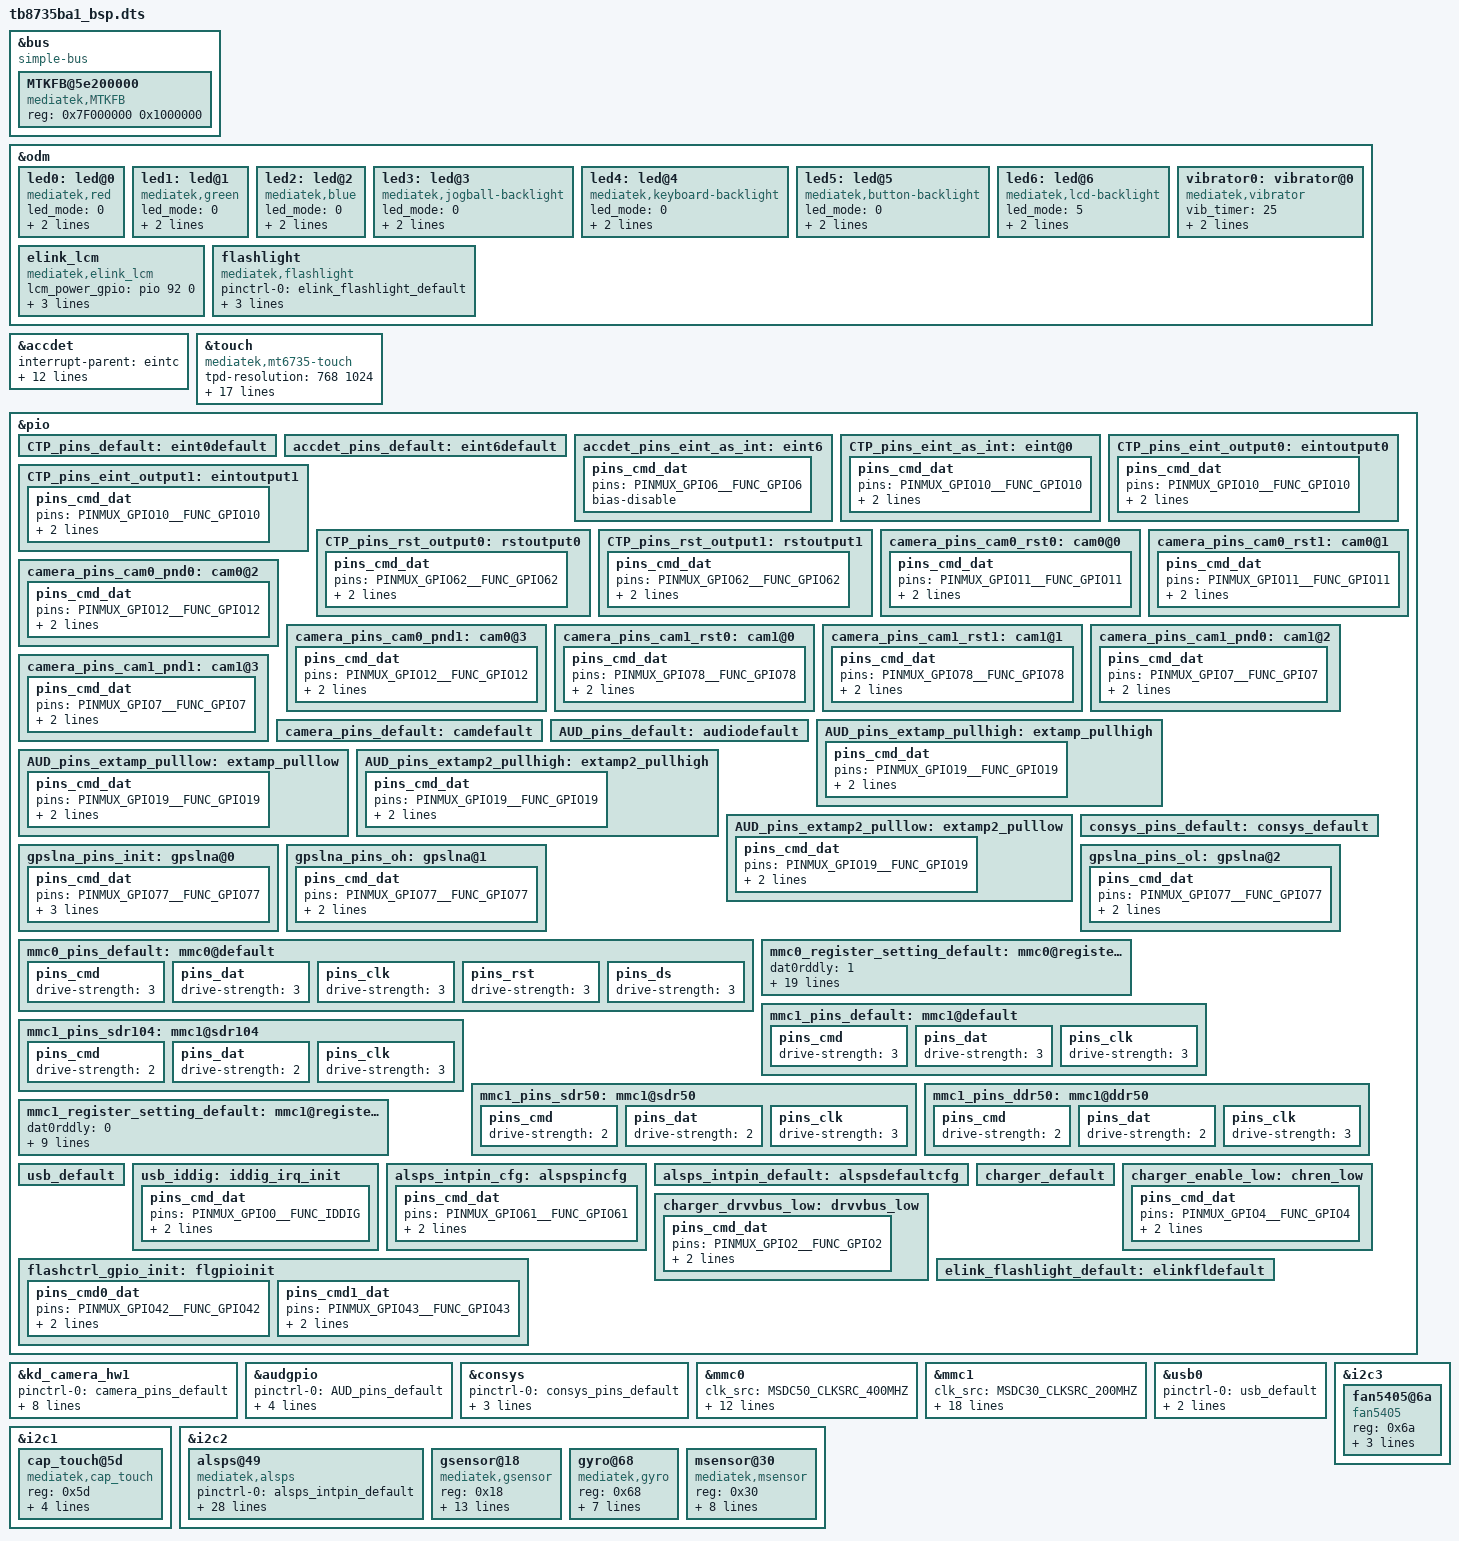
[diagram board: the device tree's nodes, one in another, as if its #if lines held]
#include <generated/autoconf.h>
/dts-v1/;

#ifdef CONFIG_MTK_DTBO_FEATURE
/plugin/;
#include "mt6735m-pinfunc.h"
#include <dt-bindings/mmc/mt67xx-msdc.h>
#include <dt-bindings/interrupt-controller/arm-gic.h>
#include <dt-bindings/interrupt-controller/irq.h>
#else
#include "mt6735m.dts"
#endif
#include "tb8735ba1_bsp_bat_setting.dtsi"



&bus {
		compatible = "simple-bus";
		#address-cells = <1>;
		#size-cells = <1>;

		MTKFB@5e200000 {
			compatible = "mediatek,MTKFB";
			reg = <0x7F000000 0x1000000>;
		};

	};
&odm {
	led0:led@0 {
		compatible = "mediatek,red";
		led_mode = <0>;
		data = <1>;
		pwm_config = <0 0 0 0 0>;
	};
	led1:led@1 {
		compatible = "mediatek,green";
		led_mode = <0>;
		data = <1>;
		pwm_config = <0 0 0 0 0>;
	};
	led2:led@2 {
		compatible = "mediatek,blue";
		led_mode = <0>;
		data = <1>;
		pwm_config = <0 0 0 0 0>;
	};
	led3:led@3 {
		compatible = "mediatek,jogball-backlight";
		led_mode = <0>;
		data = <1>;
		pwm_config = <0 0 0 0 0>;
	};
	led4:led@4 {
		compatible = "mediatek,keyboard-backlight";
		led_mode = <0>;
		data = <1>;
		pwm_config = <0 0 0 0 0>;
	};
	led5:led@5 {
		compatible = "mediatek,button-backlight";
		led_mode = <0>;
		data = <1>;
		pwm_config = <0 0 0 0 0>;
	};
	led6:led@6 {
		compatible = "mediatek,lcd-backlight";
		led_mode = <5>;
		data = <1>;
		pwm_config = <0 0 0 0 0>;
	};
	vibrator0:vibrator@0 {
		compatible = "mediatek,vibrator";
		vib_timer = <25>;
		vib_limit = <9>;
		vib_vol= <5>;
	};
	
	elink_lcm: elink_lcm {
		compatible = "mediatek,elink_lcm";
		
		lcm_power_gpio = <&pio 92 0>;
		lcm_reset_gpio = <&pio 146 0>;
		lcm_te_gpio = <&pio 147 0>;
		
		reg-lcm-supply = <&mt_pmic_vrf18_1_ldo_reg>;
	};

	flashlight: flashlight {
		compatible = "mediatek,flashlight";
	};
};

&accdet {
	interrupt-parent = <&eintc>;
	interrupts = <6 IRQ_TYPE_LEVEL_LOW>;
	eint-debounce = <256>;
	accdet-gpio = <&pio 6 0>;
	accdet-mic-vol = <7>;
	headset-mode-setting = <0x500 0x200 1 0x1f0 0x800 0x800 0x20>;
	accdet-plugout-debounce = <20>;
	/*1:ACC mode, 2:low cost without in bias, 6:low cost with in bias*/
	accdet-mic-mode = <1>;
	/*0--MD_MAX--UP_MAX--DW_MAX*/
	headset-three-key-threshold = <0 80 220 500>;
	/*0--MD_MAX--VOICE_MAX--UP_MAX--DW_MAX*/
	headset-four-key-threshold = <0 58 121 192 450>;
	pinctrl-names = "default", "state_eint_as_int";
	pinctrl-0 = <&accdet_pins_default>;
	pinctrl-1 = <&accdet_pins_eint_as_int>;
	status = "okay";
};

&touch {
	compatible = "mediatek,mt6735-touch";
	tpd-resolution = <768 1024>;
	use-tpd-button = <0>;
	tpd-key-num = <3>;
	tpd-key-local= <139 172 158 0>;
	tpd-key-dim-local = <90 883 100 40 230 883 100 40 370 883 100 40 0 0 0 0>;
	tpd-max-touch-num = <5>;
	tpd-filter-enable = <1>;
	tpd-filter-pixel-density = <93>;
	tpd-filter-custom-prameters = <0 0 0 0 0 0 0 0 0 0 0 0>;
	tpd-filter-custom-speed = <0 0 0>;
	pinctrl-names = "default", "state_eint_as_int", "state_eint_output0", "state_eint_output1",
		"state_rst_output0", "state_rst_output1";
	pinctrl-0 = <&CTP_pins_default>;
	pinctrl-1 = <&CTP_pins_eint_as_int>;
	pinctrl-2 = <&CTP_pins_eint_output0>;
	pinctrl-3 = <&CTP_pins_eint_output1>;
	pinctrl-4 = <&CTP_pins_rst_output0>;
	pinctrl-5 = <&CTP_pins_rst_output1>;
	status = "okay";
};
&pio {
	CTP_pins_default: eint0default {
	};

	accdet_pins_default: eint6default {
	};

	accdet_pins_eint_as_int: eint6 {
		pins_cmd_dat {
			pins = <PINMUX_GPIO6__FUNC_GPIO6>;
			bias-disable;
		};
	};

	CTP_pins_eint_as_int: eint@0 {
		pins_cmd_dat {
			pins = <PINMUX_GPIO10__FUNC_GPIO10>;
			slew-rate = <0>;
			bias-disable;
		};
	};
	CTP_pins_eint_output0: eintoutput0 {
		pins_cmd_dat {
			pins = <PINMUX_GPIO10__FUNC_GPIO10>;
			slew-rate = <1>;
			output-low;
		};
	};
	CTP_pins_eint_output1: eintoutput1 {
		pins_cmd_dat {
			pins = <PINMUX_GPIO10__FUNC_GPIO10>;
			slew-rate = <1>;
			output-high;
		};
	};
	CTP_pins_rst_output0: rstoutput0 {
		pins_cmd_dat {
			pins = <PINMUX_GPIO62__FUNC_GPIO62>;
			slew-rate = <1>;
			output-low;
		};
	};
	CTP_pins_rst_output1: rstoutput1 {
		pins_cmd_dat {
			pins = <PINMUX_GPIO62__FUNC_GPIO62>;
			slew-rate = <1>;
			output-high;
		};
	};
};
/* TOUCH end */
/* CAMERA GPIO standardization */
&pio {
	camera_pins_cam0_rst0: cam0@0 {
	    pins_cmd_dat {
			pins = <PINMUX_GPIO11__FUNC_GPIO11>;/*GPIO_CAMERA_CMRST_PIN*/
			slew-rate = <1>; /*direction 0:in, 1:out*/
			output-low;/*direction out used only. output_low or high*/
		};
	};
	camera_pins_cam0_rst1: cam0@1 {
	    pins_cmd_dat {
			pins = <PINMUX_GPIO11__FUNC_GPIO11>;/*GPIO_CAMERA_CMRST_PIN*/
			slew-rate = <1>;
			output-high;
		};
	};
	camera_pins_cam0_pnd0: cam0@2 {
	    pins_cmd_dat {
			pins = <PINMUX_GPIO12__FUNC_GPIO12>;/*GPIO_CAMERA_CMPDN_PIN*/
			slew-rate = <1>;
			output-low;
		};
	};
	camera_pins_cam0_pnd1: cam0@3 {
	    pins_cmd_dat {
			pins = <PINMUX_GPIO12__FUNC_GPIO12>;/*GPIO_CAMERA_CMPDN_PIN*/
			slew-rate = <1>;
			output-high;
		};
	};
	camera_pins_cam1_rst0: cam1@0 {
	    pins_cmd_dat {
			pins = <PINMUX_GPIO78__FUNC_GPIO78>;/*GPIO_CAMERA_CMRST1_PIN*/
			slew-rate = <1>; /*direction 0:in, 1:out*/
			output-low;/*direction out used only. output_low or high*/
		};
	};
	camera_pins_cam1_rst1: cam1@1 {
	    pins_cmd_dat {
			pins = <PINMUX_GPIO78__FUNC_GPIO78>;/*GPIO_CAMERA_CMRST1_PIN*/
			slew-rate = <1>;
			output-high;
		};
	};
	camera_pins_cam1_pnd0: cam1@2 {
	    pins_cmd_dat {
			pins = <PINMUX_GPIO7__FUNC_GPIO7>;/*GPIO_CAMERA_CMPDN1_PIN*/
			slew-rate = <1>;
			output-low;
		};
	};
	camera_pins_cam1_pnd1: cam1@3 {
	    pins_cmd_dat {
			pins = <PINMUX_GPIO7__FUNC_GPIO7>;/*GPIO_CAMERA_CMPDN1_PIN*/
			slew-rate = <1>;
			output-high;
		};
	};
	camera_pins_default: camdefault {
	};
};

&kd_camera_hw1 {
	pinctrl-names = "default", "cam0_rst0", "cam0_rst1", "cam0_pnd0", "cam0_pnd1",
			"cam1_rst0", "cam1_rst1", "cam1_pnd0", "cam1_pnd1";
	pinctrl-0 = <&camera_pins_default>;
	pinctrl-1 = <&camera_pins_cam0_rst0>;
	pinctrl-2 = <&camera_pins_cam0_rst1>;
	pinctrl-3 = <&camera_pins_cam0_pnd0>;
	pinctrl-4 = <&camera_pins_cam0_pnd1>;
	pinctrl-5 = <&camera_pins_cam1_rst0>;
	pinctrl-6 = <&camera_pins_cam1_rst1>;
	pinctrl-7 = <&camera_pins_cam1_pnd0>;
	pinctrl-8 = <&camera_pins_cam1_pnd1>;
	
	status = "okay";

};
/* CAMERA GPIO end */

/* AUDIO GPIO standardization */
&audgpio {
	pinctrl-names = "default", "extamp-pullhigh", "extamp-pulllow", "extamp2-pullhigh" , "extamp2-pulllow";
	pinctrl-0 = <&AUD_pins_default>;
	pinctrl-1 = <&AUD_pins_extamp_pullhigh>;
	pinctrl-2 = <&AUD_pins_extamp_pulllow>;
	pinctrl-3 = <&AUD_pins_extamp2_pullhigh>;
	pinctrl-4 = <&AUD_pins_extamp2_pulllow>;
	status = "okay";
};
&pio {
	AUD_pins_default: audiodefault {
	};

	AUD_pins_extamp_pullhigh: extamp_pullhigh {
		pins_cmd_dat {
			pins = <PINMUX_GPIO19__FUNC_GPIO19>;
			slew-rate = <1>;
			output-high;
		};
	};
	AUD_pins_extamp_pulllow: extamp_pulllow {
		pins_cmd_dat {
			pins = <PINMUX_GPIO19__FUNC_GPIO19>;
			slew-rate = <1>;
			output-low;
		};
	};

	AUD_pins_extamp2_pullhigh: extamp2_pullhigh {
		pins_cmd_dat {
			pins = <PINMUX_GPIO19__FUNC_GPIO19>;
			slew-rate = <1>;
			output-high;
		};
	};
	AUD_pins_extamp2_pulllow: extamp2_pulllow {
		pins_cmd_dat {
			pins = <PINMUX_GPIO19__FUNC_GPIO19>;
			slew-rate = <1>;
			output-low;
		};
	};
};

/* AUDIO end */
/* CONSYS GPIO standardization */
&pio {
	consys_pins_default: consys_default {

	};

	gpslna_pins_init: gpslna@0 {
		pins_cmd_dat {
			pins = <PINMUX_GPIO77__FUNC_GPIO77>;
			slew-rate = <0>;
			bias-disable;
			output-low;
		};
	};

	gpslna_pins_oh: gpslna@1 {
		pins_cmd_dat {
			pins = <PINMUX_GPIO77__FUNC_GPIO77>;
			slew-rate = <1>;
			output-high;
		};
	};

	gpslna_pins_ol: gpslna@2 {
		pins_cmd_dat {
			pins = <PINMUX_GPIO77__FUNC_GPIO77>;
			slew-rate = <1>;
			output-low;
		};
	};
};

&consys {
	pinctrl-names = "default", "gps_lna_state_init", "gps_lna_state_oh", "gps_lna_state_ol";
	pinctrl-0 = <&consys_pins_default>;
	pinctrl-1 = <&gpslna_pins_init>;
	pinctrl-2 = <&gpslna_pins_oh>;
	pinctrl-3 = <&gpslna_pins_ol>;
	status = "okay";
};
/* CONSYS end */

/* mmc start */
&mmc0 {
		clk_src = /bits/ 8 <MSDC50_CLKSRC_400MHZ>;
		bus-width = <8>;
		max-frequency = <200000000>;
		cap-mmc-highspeed;
		msdc-sys-suspend;
		mmc-ddr-1_8v;
		mmc-hs200-1_8v;
		//mmc-hs400-1_8v;
		non-removable;
		pinctl = <&mmc0_pins_default>;
		register_setting = <&mmc0_register_setting_default>;
		host_function = /bits/ 8 <MSDC_EMMC>;
		bootable;
		status = "okay";
};

&mmc1 {
		clk_src = /bits/ 8 <MSDC30_CLKSRC_200MHZ>;
		bus-width = <4>;
		max-frequency = <200000000>;
		msdc-sys-suspend;
		//sd_need_power;
		cap-sd-highspeed;
		sd-uhs-sdr12;
		sd-uhs-sdr25;
		sd-uhs-sdr50;
		sd-uhs-sdr104;
		sd-uhs-ddr50;
		pinctl = <&mmc1_pins_default>;
		pinctl_sdr104 = <&mmc1_pins_sdr104>;
		pinctl_sdr50 = <&mmc1_pins_sdr50>;
		pinctl_ddr50 = <&mmc1_pins_ddr50>;
		register_setting = <&mmc1_register_setting_default>;
		host_function = /bits/ 8 <MSDC_SD>;
		cd_level = /bits/ 8 <MSDC_CD_LOW>;
		cd-gpios = <&pio 5 0>;
		status = "okay";
};

&pio {
	mmc0_pins_default: mmc0@default {
			pins_cmd {
				drive-strength = /bits/ 8 <3>;
			};
			pins_dat {
				drive-strength = /bits/ 8 <3>;
			};
			pins_clk {
				drive-strength = /bits/ 8 <3>;
			};
			pins_rst {
				drive-strength = /bits/ 8 <3>;
			};
			pins_ds {
				drive-strength = /bits/ 8 <3>;
			};
	};

	mmc0_register_setting_default: mmc0@register_default {
		dat0rddly      = /bits/ 8 <1>;
		dat1rddly      = /bits/ 8 <1>;
		dat2rddly      = /bits/ 8 <1>;
		dat3rddly      = /bits/ 8 <1>;
		dat4rddly      = /bits/ 8 <1>;
		dat5rddly      = /bits/ 8 <1>;
		dat6rddly      = /bits/ 8 <1>;
		dat7rddly      = /bits/ 8 <1>;
		datwrddly      = /bits/ 8 <1>;
		cmdrrddly      = /bits/ 8 <1>;
		cmdrddly       = /bits/ 8 <1>;
		cmd_edge = /bits/ 8 <MSDC_SMPL_FALLING>;
		rdata_edge = /bits/ 8 <MSDC_SMPL_FALLING>;
		wdata_edge = /bits/ 8 <MSDC_SMPL_FALLING>;

		ett-hs200-cells = <12>;
		ett-hs200-default = <OFFSET_MSDC_PATCH_BIT0	MSDC_PB0_INT_DAT_LATCH_CK_SEL 0x0
			OFFSET_MSDC_PATCH_BIT0	MSDC_PB0_CKGEN_MSDC_DLY_SEL   0x0
			OFFSET_MSDC_PATCH_BIT1	MSDC_PB1_CMD_RSP_TA_CNTR      0x1
			OFFSET_MSDC_IOCON		MSDC_IOCON_RSPL               0x0
			OFFSET_MSDC_PAD_TUNE0	MSDC_PAD_TUNE0_CMDRDLY        0x7
			OFFSET_MSDC_PAD_TUNE0	MSDC_PAD_TUNE0_CMDRRDLY       0xb
			OFFSET_MSDC_PATCH_BIT1		MSDC_PB1_WRDAT_CRCS_TA_CNTR   0x1
			OFFSET_MSDC_PAD_TUNE0	MSDC_PAD_TUNE0_DATWRDLY       0xb
			OFFSET_MSDC_IOCON			MSDC_IOCON_W_D0SPL            0x0
			OFFSET_MSDC_DAT_RDDLY0		MSDC_DAT_RDDLY0_D0            0x7
			OFFSET_MSDC_PAD_TUNE0	MSDC_PAD_TUNE0_DATRRDLY       0x9
			OFFSET_MSDC_IOCON		MSDC_IOCON_R_D_SMPL           0x0>;

		ett-hs400-cells = <8>;
		ett-hs400-default = <OFFSET_MSDC_PATCH_BIT0	MSDC_PB0_INT_DAT_LATCH_CK_SEL	0x0
			OFFSET_MSDC_PATCH_BIT0		MSDC_PB0_CKGEN_MSDC_DLY_SEL		0x0
			OFFSET_EMMC50_PAD_DS_TUNE	MSDC_EMMC50_PAD_DS_TUNE_DLY1	0x2
			OFFSET_EMMC50_PAD_DS_TUNE	MSDC_EMMC50_PAD_DS_TUNE_DLY3	0x10
			OFFSET_MSDC_PATCH_BIT1			MSDC_PB1_CMD_RSP_TA_CNTR	0x1
			OFFSET_MSDC_IOCON		MSDC_IOCON_RSPL				0x0
			OFFSET_MSDC_PAD_TUNE0			MSDC_PAD_TUNE0_CMDRDLY		0x6
			OFFSET_MSDC_PAD_TUNE0		MSDC_PAD_TUNE0_CMDRRDLY		0x6>;
	};

	mmc1_pins_default: mmc1@default {
			pins_cmd {
				drive-strength = /bits/ 8 <3>;
			};
			pins_dat {
				drive-strength = /bits/ 8 <3>;
			};
			pins_clk {
				drive-strength = /bits/ 8 <3>;
			};
	};

	mmc1_pins_sdr104: mmc1@sdr104 {
			pins_cmd {
				drive-strength = /bits/ 8 <2>;
			};
			pins_dat {
				drive-strength = /bits/ 8 <2>;
			};
			pins_clk {
				drive-strength = /bits/ 8 <3>;
			};
	};

	mmc1_pins_sdr50: mmc1@sdr50 {
			pins_cmd {
				drive-strength = /bits/ 8 <2>;
			};
			pins_dat {
				drive-strength = /bits/ 8 <2>;
			};
			pins_clk {
				drive-strength = /bits/ 8 <3>;
			};
	};

	mmc1_pins_ddr50: mmc1@ddr50 {
			pins_cmd {
				drive-strength = /bits/ 8 <2>;
			};
			pins_dat {
				drive-strength = /bits/ 8 <2>;
			};
			pins_clk {
				drive-strength = /bits/ 8 <3>;
			};
	};

	mmc1_register_setting_default: mmc1@register_default {
				dat0rddly      = /bits/ 8 <0>;
				dat1rddly      = /bits/ 8 <0>;
				dat2rddly      = /bits/ 8 <0>;
				dat3rddly      = /bits/ 8 <0>;
				datwrddly      = /bits/ 8 <0>;
				cmdrrddly      = /bits/ 8 <0>;
				cmdrddly       = /bits/ 8 <0>;
				cmd_edge = /bits/ 8 <MSDC_SMPL_FALLING>;
				rdata_edge = /bits/ 8 <MSDC_SMPL_FALLING>;
				wdata_edge = /bits/ 8 <MSDC_SMPL_FALLING>;
	};
};
/* mmc end */
/* USB GPIO Kernal Standardization start */
&pio {
	usb_default: usb_default {
	};

	usb_iddig: iddig_irq_init {
		pins_cmd_dat {
			pins = <PINMUX_GPIO0__FUNC_IDDIG>;
			slew-rate = <0>;
			bias-pull-up = <00>;
		};
	};
};

&usb0 {
	pinctrl-names = "usb_default", "iddig_irq_init";
	pinctrl-0 = <&usb_default>;
	pinctrl-1 = <&usb_iddig>;
	iddig_gpio = <0 1>;
	
	status = "okay";
};
/* USB GPIO Kernal Standardization end */

&i2c1 {
/*
	silead_touch@5D {
		compatible = "mediatek,silead_touch";
		reg = <0x5D>;
		
		interrupt-parent = <&eintc>;
		interrupts = <10 IRQ_TYPE_EDGE_FALLING>;
		debounce = <10 0>;
	};
*/

	cap_touch@5d {
		compatible = "mediatek,cap_touch";
		reg = <0x5d>;
		interrupt-parent = <&pio>;
		interrupts = <10 IRQ_TYPE_EDGE_FALLING>;
		// interrupts = <10 IRQ_TYPE_LEVEL_LOW>;
		int-gpio = <&pio 10 0>;
		rst-gpio = <&pio 62 0>;
		/*vtouch1-supply = <&mt6323_vgp2_reg>;*/
	};
};

&pio {
	alsps_intpin_cfg: alspspincfg {
		pins_cmd_dat {
			pins = <PINMUX_GPIO61__FUNC_GPIO61>;
			slew-rate = <0>;
			bias-pull-up = <00>;
		};
	};

	alsps_intpin_default: alspsdefaultcfg {
	};
};

&i2c2 {
	alsps@49 {
		compatible = "mediatek,alsps";
		pinctrl-names = "pin_default", "pin_cfg";
		pinctrl-0 = <&alsps_intpin_default>;
		pinctrl-1 = <&alsps_intpin_cfg>;

		interrupt-parent = <&eintc>;
		interrupts = <61 IRQ_TYPE_LEVEL_LOW>;
		debounce = <61 0>;
		
		i2c_num = <2>;
		reg = <0x49>;
		polling_mode_ps = <0>;
		polling_mode_als = <1>;
		is_batch_supported_ps = <0>;
		is_batch_supported_als = <0>;
		is_batch_supported = <0>;
		power_id = <0xffff>;
		power_vol = <0>;
		firlen = <16>;
		
		/* epl259x */
		epl259x_addr = <0x49 0 0 0>;
		epl259x_level = <20 45 70 90 150 300 500 700 1150 2250 4500 8000 15000 30000 50000>;
		epl259x_value = <10 30 60 80 100 200 400 600 800 1500 3000 6000 10000 20000 40000 60000>;
		epl259x_thld_high =  <800>;
		epl259x_thld_low =  <500>;

		/* stk3x1x */
		stk3x1x_addr = <0x48 0 0 0>;
		stk3x1x_level = <5 9 36 59 82 132 205 273 500 845 1136 1545 2364 4655 6982>;
		stk3x1x_value = <30 40 80 130 180 290 450 600 1100 1860 2500 3400 5200 10240 10240 10240>;
		stk3x1x_thld_high = <1700>;
		stk3x1x_thld_low = <1500>;

		status = "okay";
	};
	
    gsensor@18 {
		compatible = "mediatek,gsensor";
		reg = <0x18>;
		i2c_num = <2>;
		power_id = <0xffff>;
		power_vol = <0>;
		firlen = <16>;
		is_batch_supported = <0>;

		/* bma222e */
		bma222e_addr = <0x18 0 0 0>;
		bma222e_direction = <5>;

		/* stk8baxx */
		stk8baxx_addr = <0x18 0 0 0>;
		stk8baxx_direction = <5>;

		/* mc34xx */
		mc34xx_addr = <0x4c 0 0 0>;
		mc34xx_direction = <5>;

		/* mpu6050g */
		mpu6050g_addr = <0x68 0 0 0>;
		mpu6050g_direction = <0>;

		status = "okay";
    };
	
    gyro@68 {
		compatible = "mediatek,gyro";
		reg = <0x68>;
		i2c_num = <2>;
		power_id = <0xffff>;
		power_vol = <0>;
		firlen = <0>;
		is_batch_supported = <0>;

		/* mpu6050gy */
		mpu6050gy_addr = <0x68 0 0 0>;
		mpu6050gy_direction = <0>;

		status = "okay";
    };
    
    msensor@30 {
		compatible = "mediatek,msensor";
		reg = <0x30>;
		i2c_num = <2>;
		power_id = <0xffff>;
		power_vol = <0>;
		is_batch_supported = <0>;

		/* mmc3416x */
		mmc3416x_addr = <0x30 0 0 0>;
		mmc3416x_direction = <1>;

		/* mmc3630x */
		mmc3630x_addr = <0x30 0 0 0>;
		mmc3630x_direction = <1>;

		status = "okay";
    };
};

&pio {
	charger_default: charger_default {
	};
	
	charger_enable_low: chren_low {
		pins_cmd_dat {
			pins = <PINMUX_GPIO4__FUNC_GPIO4>;
			slew-rate = <1>;
			output-low;
		};
	};
	
	charger_drvvbus_low: drvvbus_low {
		pins_cmd_dat {
			pins = <PINMUX_GPIO2__FUNC_GPIO2>;
			slew-rate = <1>;
			output-low;
		};
	};
};

&i2c3 {
	fan5405@6a {
		status = "okay";
		compatible = "fan5405";
		reg = <0x6a>;
		pinctrl-names = "charger_default", "chren_low", "drvvbus_low";
		pinctrl-0 = <&charger_default>;
		pinctrl-1 = <&charger_enable_low>;
		pinctrl-2 = <&charger_drvvbus_low>;
	};
};
/* i2c end */

&pio {
	flashctrl_gpio_init: flgpioinit {
	    pins_cmd0_dat {
			pins = <PINMUX_GPIO42__FUNC_GPIO42>;
			slew-rate = <1>;
			output-low;
		};

		pins_cmd1_dat {
			pins = <PINMUX_GPIO43__FUNC_GPIO43>;
			slew-rate = <1>;
			output-low;
		};
	};
	
	elink_flashlight_default: elinkfldefault {
	};
};

&flashlight {
	pinctrl-names = "elink_flashlight_default", "flashctrl_gpio_init";
	pinctrl-0 = <&elink_flashlight_default>;
	pinctrl-1 = <&flashctrl_gpio_init>;

	main_enable_gpio = <&pio 43 0>;
	main_flash_gpio = <&pio 42 0>;
};

#include <tb8735ba1_bsp/cust.dtsi>
/*End of this file, DO NOT ADD ANYTHING HERE*/
